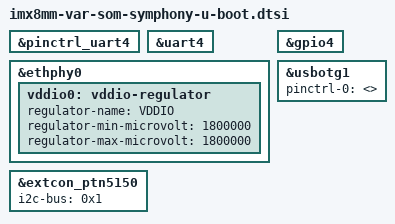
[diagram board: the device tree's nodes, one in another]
// SPDX-License-Identifier: GPL-2.0+
/*
 * Copyright 2018 NXP
 * Copyright 2018-2025 Variscite Ltd.
 */

#include "imx8mm-var-common-u-boot.dtsi"

&pinctrl_uart4 {
	bootph-pre-ram;
};

&uart4 {
	bootph-pre-ram;
};

&ethphy0 {
	vddio0: vddio-regulator {
		regulator-name = "VDDIO";
		regulator-min-microvolt = <1800000>;
		regulator-max-microvolt = <1800000>;
	};
};

&gpio4 {
	bootph-pre-ram;
};

&extcon_ptn5150 {
	i2c-bus = <0x1>;
};

&usbotg1 {
	pinctrl-names = "default";
	pinctrl-0 = <>;
};
